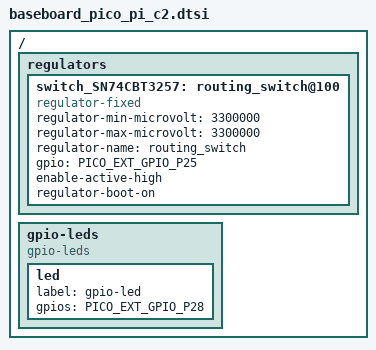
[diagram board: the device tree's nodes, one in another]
/*
 * Copyright 2018 Technexion Ltd.
 *
 * Author: Tapani Utriainen <tapani@technexion.com>
 *         Richard Hu <richard.hu@technexion.com>
 *
 * This program is free software; you can redistribute it and/or modify
 * it under the terms of the GNU General Public License version 2 as
 * published by the Free Software Foundation.
 *
 */

#include "baseboard_pico_pi.dtsi"

/ {
    /*
       Choose the four pins routed to J8
       High: I2S3_TXC, I2S3_TXFS, I2S3_RXD, I2S3_TXD
       Low:  PWM1, GPIO_P24, CAN2_TX, CAN2_RX
    */
    regulators {
	switch_SN74CBT3257: routing_switch@100 {
		compatible = "regulator-fixed";
		regulator-min-microvolt = <3300000>;
		regulator-max-microvolt = <3300000>;
		regulator-name = "routing_switch";
		gpio = <&PICO_EXT_GPIO_P25 GPIO_ACTIVE_HIGH>;
		enable-active-high;
		regulator-boot-on;
	};
    };

    gpio-leds {
	compatible = "gpio-leds";

	led {
		label = "gpio-led";
		gpios = <&PICO_EXT_GPIO_P28 GPIO_ACTIVE_HIGH>; /* PICO_P28 */
	};
    };
};
